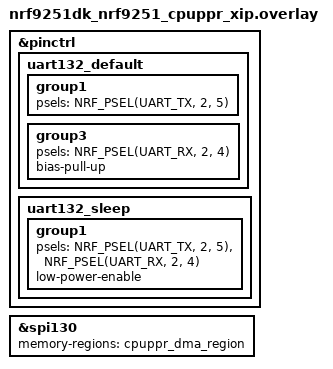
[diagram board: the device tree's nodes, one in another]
/*
 * Copyright (c) 2026 Nordic Semiconductor ASA
 *
 * SPDX-License-Identifier: LicenseRef-Nordic-5-Clause
 */

#include "nrf9251dk_nrf9251_cpuapp.overlay"

&pinctrl {
	/* Console without RTS/CTS, as P2.06 and P2.08 are used by the test. */
	uart132_default: uart132_default {
		group1 {
			psels = <NRF_PSEL(UART_TX, 2, 5)>;
		};

		group3 {
			psels = <NRF_PSEL(UART_RX, 2, 4)>;
			bias-pull-up;
		};
	};

	uart132_sleep: uart132_sleep {
		group1 {
			psels = <NRF_PSEL(UART_TX, 2, 5)>,
				<NRF_PSEL(UART_RX, 2, 4)>;
			low-power-enable;
		};
	};
};

&spi130 {
	memory-regions = <&cpuppr_dma_region>;
};
